# ESP8266 register map
File version: 1.0
CPU: Xtensa LX106 1, little endian, no MPU, FPU, 3 interrupt priority bits
Registers are 32-bit, read-write, reset 0x0 unless marked. A register's access mark holds for its fields unless they carry their own. Offsets are from the block's base; [hi:lo] are bit positions; {n}, {i} and the like mark numbered series.

## SLC
Base 0x60000B00
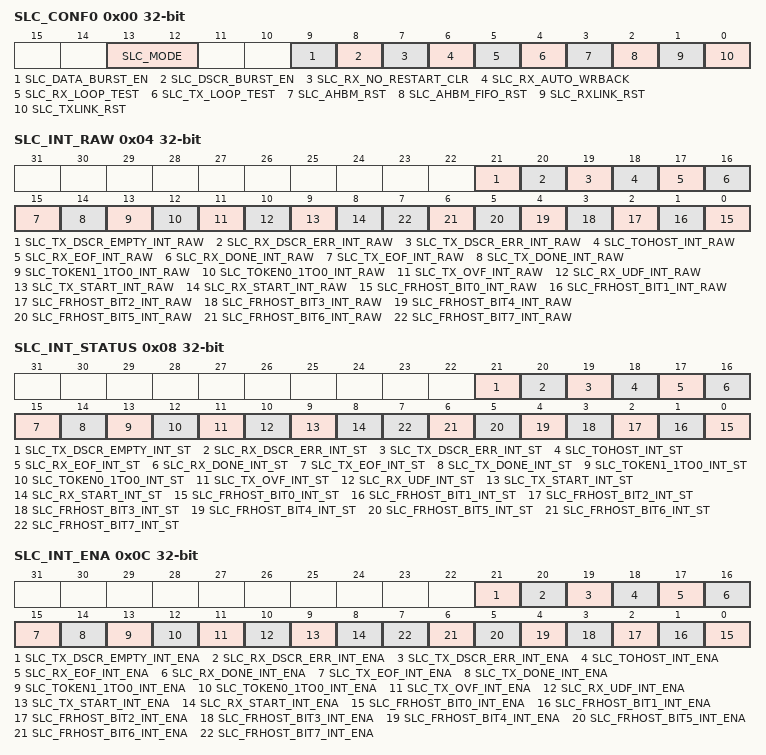
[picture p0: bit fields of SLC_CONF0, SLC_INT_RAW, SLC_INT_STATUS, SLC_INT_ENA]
0x00 SLC_CONF0
  [13:12] SLC_MODE, [9] SLC_DATA_BURST_EN, [8] SLC_DSCR_BURST_EN, [7] SLC_RX_NO_RESTART_CLR, [6] SLC_RX_AUTO_WRBACK, [5] SLC_RX_LOOP_TEST, [4] SLC_TX_LOOP_TEST, [3] SLC_AHBM_RST, [2] SLC_AHBM_FIFO_RST, [1] SLC_RXLINK_RST, [0] SLC_TXLINK_RST
0x04 SLC_INT_RAW
  [21] SLC_TX_DSCR_EMPTY_INT_RAW, [20] SLC_RX_DSCR_ERR_INT_RAW, [19] SLC_TX_DSCR_ERR_INT_RAW, [18] SLC_TOHOST_INT_RAW, [17] SLC_RX_EOF_INT_RAW, [16] SLC_RX_DONE_INT_RAW, [15] SLC_TX_EOF_INT_RAW, [14] SLC_TX_DONE_INT_RAW, [13] SLC_TOKEN1_1TO0_INT_RAW, [12] SLC_TOKEN0_1TO0_INT_RAW, [11] SLC_TX_OVF_INT_RAW, [10] SLC_RX_UDF_INT_RAW, [9] SLC_TX_START_INT_RAW, [8] SLC_RX_START_INT_RAW, [n] SLC_FRHOST_BIT{n}_INT_RAW (n=0..7)
0x08 SLC_INT_STATUS
  [21] SLC_TX_DSCR_EMPTY_INT_ST, [20] SLC_RX_DSCR_ERR_INT_ST, [19] SLC_TX_DSCR_ERR_INT_ST, [18] SLC_TOHOST_INT_ST, [17] SLC_RX_EOF_INT_ST, [16] SLC_RX_DONE_INT_ST, [15] SLC_TX_EOF_INT_ST, [14] SLC_TX_DONE_INT_ST, [13] SLC_TOKEN1_1TO0_INT_ST, [12] SLC_TOKEN0_1TO0_INT_ST, [11] SLC_TX_OVF_INT_ST, [10] SLC_RX_UDF_INT_ST, [9] SLC_TX_START_INT_ST, [8] SLC_RX_START_INT_ST, [n] SLC_FRHOST_BIT{n}_INT_ST (n=0..7)
0x0C SLC_INT_ENA
  [21] SLC_TX_DSCR_EMPTY_INT_ENA, [20] SLC_RX_DSCR_ERR_INT_ENA, [19] SLC_TX_DSCR_ERR_INT_ENA, [18] SLC_TOHOST_INT_ENA, [17] SLC_RX_EOF_INT_ENA, [16] SLC_RX_DONE_INT_ENA, [15] SLC_TX_EOF_INT_ENA, [14] SLC_TX_DONE_INT_ENA, [13] SLC_TOKEN1_1TO0_INT_ENA, [12] SLC_TOKEN0_1TO0_INT_ENA, [11] SLC_TX_OVF_INT_ENA, [10] SLC_RX_UDF_INT_ENA, [9] SLC_TX_START_INT_ENA, [8] SLC_RX_START_INT_ENA, [n] SLC_FRHOST_BIT{n}_INT_ENA (n=0..7)
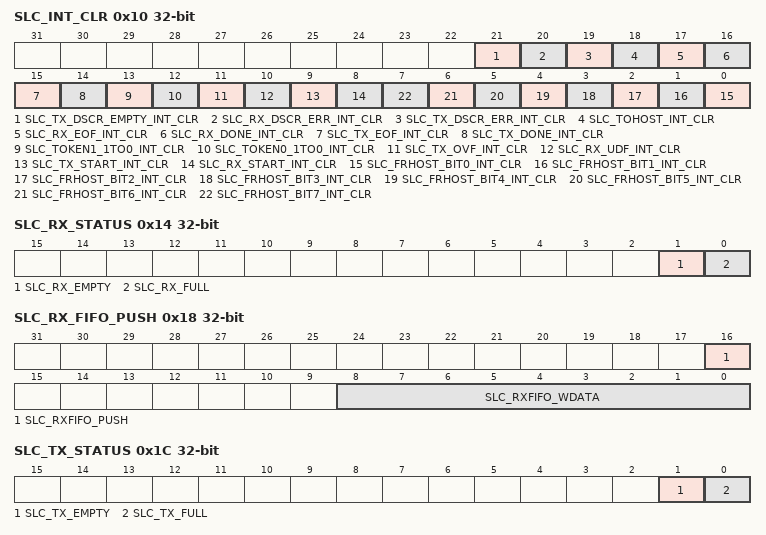
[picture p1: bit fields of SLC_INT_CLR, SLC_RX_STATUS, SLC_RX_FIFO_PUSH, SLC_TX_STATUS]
0x10 SLC_INT_CLR
  [21] SLC_TX_DSCR_EMPTY_INT_CLR, [20] SLC_RX_DSCR_ERR_INT_CLR, [19] SLC_TX_DSCR_ERR_INT_CLR, [18] SLC_TOHOST_INT_CLR, [17] SLC_RX_EOF_INT_CLR, [16] SLC_RX_DONE_INT_CLR, [15] SLC_TX_EOF_INT_CLR, [14] SLC_TX_DONE_INT_CLR, [13] SLC_TOKEN1_1TO0_INT_CLR, [12] SLC_TOKEN0_1TO0_INT_CLR, [11] SLC_TX_OVF_INT_CLR, [10] SLC_RX_UDF_INT_CLR, [9] SLC_TX_START_INT_CLR, [8] SLC_RX_START_INT_CLR, [n] SLC_FRHOST_BIT{n}_INT_CLR (n=0..7)
0x14 SLC_RX_STATUS
  [1] SLC_RX_EMPTY, [0] SLC_RX_FULL
0x18 SLC_RX_FIFO_PUSH
  [16] SLC_RXFIFO_PUSH, [8:0] SLC_RXFIFO_WDATA
0x1C SLC_TX_STATUS
  [1] SLC_TX_EMPTY, [0] SLC_TX_FULL
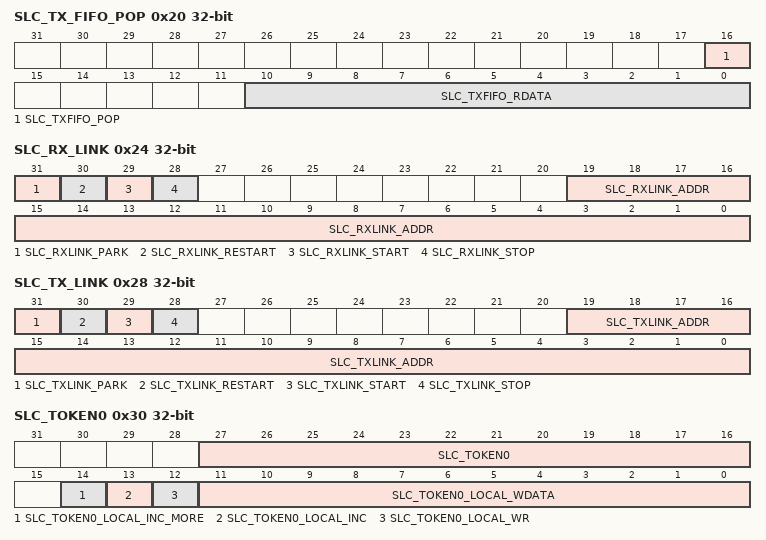
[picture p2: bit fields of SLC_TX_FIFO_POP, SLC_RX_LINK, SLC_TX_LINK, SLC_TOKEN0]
0x20 SLC_TX_FIFO_POP
  [16] SLC_TXFIFO_POP, [10:0] SLC_TXFIFO_RDATA
0x24 SLC_RX_LINK
  [31] SLC_RXLINK_PARK, [30] SLC_RXLINK_RESTART, [29] SLC_RXLINK_START, [28] SLC_RXLINK_STOP, [19:0] SLC_RXLINK_ADDR
0x28 SLC_TX_LINK
  [31] SLC_TXLINK_PARK, [30] SLC_TXLINK_RESTART, [29] SLC_TXLINK_START, [28] SLC_TXLINK_STOP, [19:0] SLC_TXLINK_ADDR
0x2C SLC_INTVEC_TOHOST
  [7:0] SLC_TOHOST_INTVEC
0x30 SLC_TOKEN0
  [27:16] SLC_TOKEN0, [14] SLC_TOKEN0_LOCAL_INC_MORE, [13] SLC_TOKEN0_LOCAL_INC, [12] SLC_TOKEN0_LOCAL_WR, [11:0] SLC_TOKEN0_LOCAL_WDATA
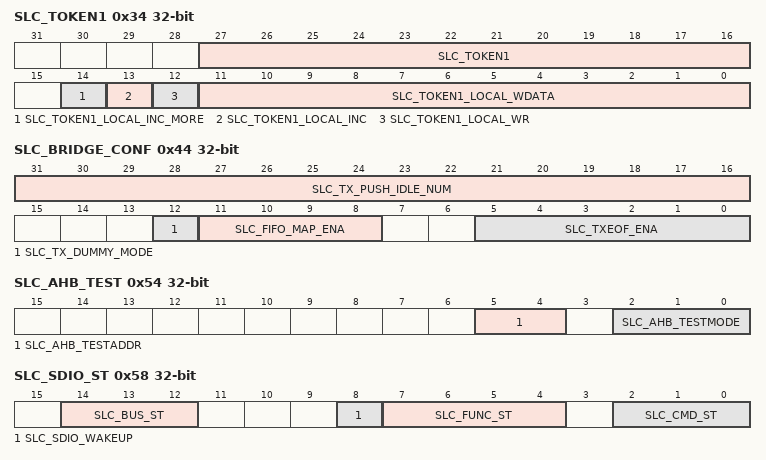
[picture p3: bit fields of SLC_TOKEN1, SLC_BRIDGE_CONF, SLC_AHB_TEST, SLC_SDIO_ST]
0x34 SLC_TOKEN1
  [27:16] SLC_TOKEN1, [14] SLC_TOKEN1_LOCAL_INC_MORE, [13] SLC_TOKEN1_LOCAL_INC, [12] SLC_TOKEN1_LOCAL_WR, [11:0] SLC_TOKEN1_LOCAL_WDATA
0x38 SLC_CONF1
  [31:0] Register
0x3C SLC_STATE0
  [31:0] Register
0x40 SLC_STATE1
  [31:0] Register
0x44 SLC_BRIDGE_CONF
  [31:16] SLC_TX_PUSH_IDLE_NUM, [12] SLC_TX_DUMMY_MODE, [11:8] SLC_FIFO_MAP_ENA, [5:0] SLC_TXEOF_ENA
0x48 SLC_RX_EOF_DES_ADDR
  [31:0] Register
0x4C SLC_TX_EOF_DES_ADDR
  [31:0] Register
0x50 SLC_RX_EOF_BFR_DES_ADDR
  [31:0] Register
0x54 SLC_AHB_TEST
  [5:4] SLC_AHB_TESTADDR, [2:0] SLC_AHB_TESTMODE
0x58 SLC_SDIO_ST
  [14:12] SLC_BUS_ST, [8] SLC_SDIO_WAKEUP, [7:4] SLC_FUNC_ST, [2:0] SLC_CMD_ST
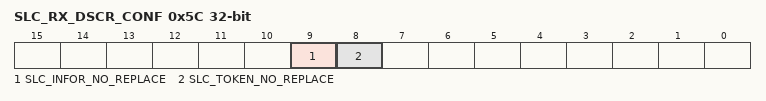
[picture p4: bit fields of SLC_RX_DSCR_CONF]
0x5C SLC_RX_DSCR_CONF
  [9] SLC_INFOR_NO_REPLACE, [8] SLC_TOKEN_NO_REPLACE
0x60 SLC_TXLINK_DSCR
  [31:0] Register
0x64 SLC_TXLINK_DSCR_BF0
  [31:0] Register
0x68 SLC_TXLINK_DSCR_BF1
  [31:0] Register
0x6C SLC_RXLINK_DSCR
  [31:0] Register
0x70 SLC_RXLINK_DSCR_BF0
  [31:0] Register
0x74 SLC_RXLINK_DSCR_BF1
  [31:0] Register
0x78 SLC_DATE
  [31:0] Register
0x7C SLC_ID
  [31:0] Register
